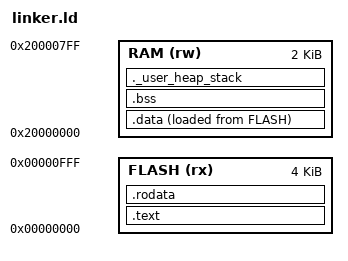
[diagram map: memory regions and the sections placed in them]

/* Entry Point */
ENTRY(_start);

/* Used to double the adressing range of a single instruction */
PROVIDE( __global_pointer$ = . + 0x800 );

/* Highest address of the user mode stack */
_estack = ORIGIN(RAM) + LENGTH(RAM);	/* end of "RAM" Ram type memory */

_Min_Heap_Size = 0x000 ;	/* required amount of heap  */
_Min_Stack_Size = 0x100 ;	/* required amount of stack */

/* Memories definition */
MEMORY
{
  RAM      (rw)    : ORIGIN = 0x20000000,   LENGTH = 2K   /* Read only and Read/Write */
  FLASH    (rx)    : ORIGIN = 0x00000000,   LENGTH = 4K	  /* Read only Execute */
}

/* Sections */
SECTIONS
{
  /* The program code and other data into "FLASH" Rom type memory */
  .text :
  {
    . = ALIGN(4);
    /*.text._start*/
    *(.text)           /* .text sections (code) */
    *(.text*)          /* .text* sections (code) */

    . = ALIGN(4);
    _etext = .;        /* define a global symbols at end of code */
  } >FLASH

  /* Constant data into "FLASH" Rom type memory */
  .rodata :
  {
    . = ALIGN(4);
    *(.rodata)         /* .rodata sections (constants, strings, etc.) */
    *(.rodata*)        /* .rodata* sections (constants, strings, etc.) */
    . = ALIGN(4);
  } >FLASH

  /* Initialized data sections into "RAM" Ram type memory */
  .data : 
  {
    . = ALIGN(4);
    _sdata = .;        /* create a global symbol at data start */
    *(.data)           /* .data sections */
    *(.data*)          /* .data* sections */

    . = ALIGN(4);
    _edata = .;        /* define a global symbol at data end */
  } >RAM AT> FLASH

  /* Uninitialized data section into "RAM" Ram type memory */
  . = ALIGN(4);
  .bss :
  {
    /* This is used by the startup in order to initialize the .bss section */
    _sbss = .;         /* define a global symbol at bss start */
    __bss_start__ = _sbss;
    *(.bss)
    *(.bss*)
    *(COMMON)

    . = ALIGN(4);
    _ebss = .;         /* define a global symbol at bss end */
    __bss_end__ = _ebss;
  } >RAM

  /* User_heap_stack section, used to check that there is enough "RAM" Ram  type memory left */
  ._user_heap_stack :
  {
    . = ALIGN(8);
    PROVIDE ( end = . );
    PROVIDE ( _end = . );
    . = . + _Min_Heap_Size;
    . = . + _Min_Stack_Size;
    . = ALIGN(8);
  } >RAM

}


